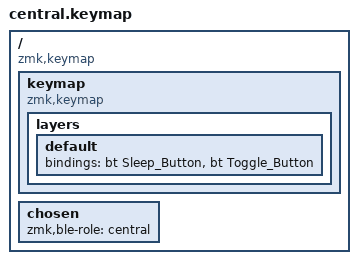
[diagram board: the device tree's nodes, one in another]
/ {
    compatible = "zmk,keymap";

    keymap {
        compatible = "zmk,keymap";

        layers {
            default {
                //TODO: fix this so it sends macros
                bindings = <
                    &bt Sleep_Button   &bt Toggle_Button
                >;
            };
        };
    };

    chosen {
        zmk,ble-role = "central";
    };
};
